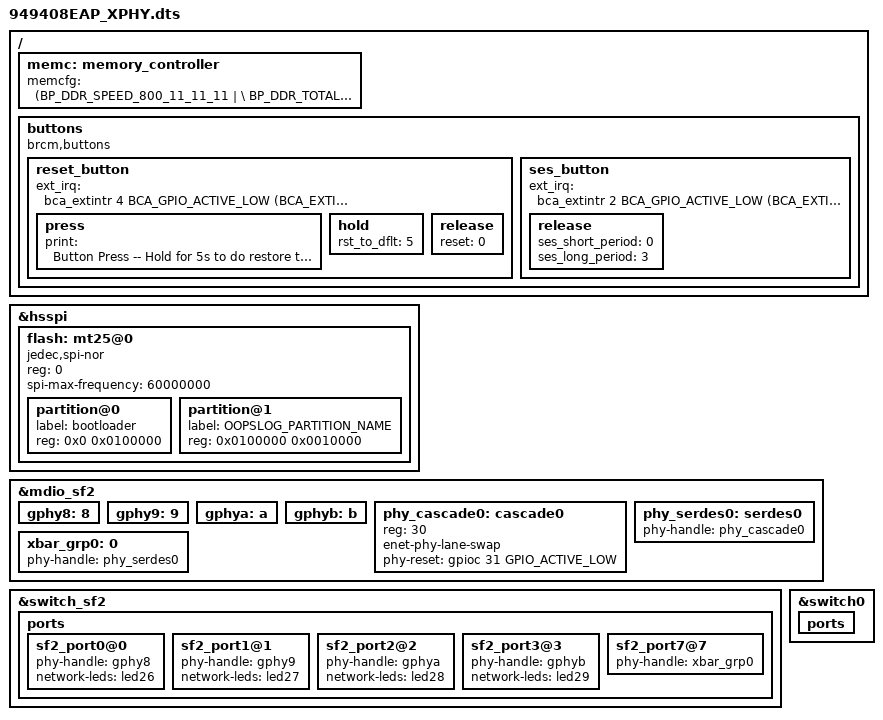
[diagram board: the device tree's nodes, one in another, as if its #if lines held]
#include "4908.dtsi"
#include "949408EAP_leds.dtsi"

/ {
    memc: memory_controller {
        memcfg = <(BP_DDR_SPEED_800_11_11_11 | \
                   BP_DDR_TOTAL_SIZE_1024MB  | \
                   BP_DDR_DEVICE_WIDTH_16    | \
                   BP_DDR_TOTAL_WIDTH_32BIT  | \
                   BP_DDR_SSC_CONFIG_1)>;
    };

	buttons {
		compatible = "brcm,buttons";
		reset_button {
			ext_irq = <&bca_extintr 4 BCA_GPIO_ACTIVE_LOW (BCA_EXTINTR_TYPE_LOW_LEVEL | BCA_EXTINTR_TYPE_SENSE_LEVEL)>;
			press {
				print = "Button Press -- Hold for 5s to do restore to default";
			};
			hold {
				rst_to_dflt = <5>;
			};
			release {
				reset = <0>;
			};	
		};
		ses_button {
			ext_irq = <&bca_extintr 2 BCA_GPIO_ACTIVE_LOW (BCA_EXTINTR_TYPE_LOW_LEVEL | BCA_EXTINTR_TYPE_SENSE_LEVEL)>;
			release {
				ses_short_period = <0>;
				ses_long_period = <3>;
			};
		};
	};
};

&hsspi { 
      flash: mt25@0 {
      status = "okay";
      compatible = "jedec,spi-nor";
      reg = <0>; /* chip select 0 */
      spi-max-frequency = <60000000>;
      #address-cells = <1>;
      #size-cells = <1>;

#if defined (CONFIG_BCM_HND_EAP)
      partition@0 {
           label = "bootloader";
           reg = <0x0 0x0100000>;
      };
#if defined (OOPSLOG_PARTITION_NAME)
      partition@1 {
           label = OOPSLOG_PARTITION_NAME;
           reg = <0x0100000 0x0010000>;
      };
#endif
#endif
      };
};

&mdio_sf2 {
	/* PHYs directly connected to SF2 */
	gphy8:8 {
		status = "okay";
	};
	gphy9:9 {
		status = "okay";
	};
	gphya:a {
		status = "okay";
	};
	gphyb:b {
		status = "okay";
	};

	/* Cascade PHY */
	phy_cascade0:cascade0 {
		reg = <30>;
		enet-phy-lane-swap;
		phy-reset = <&gpioc 31 GPIO_ACTIVE_LOW>;
		status = "okay";
	};
	
	/* PHYs connected to crossbar */
	phy_serdes0:serdes0 {
		phy-handle = <&phy_cascade0>;
		status = "okay";
	};

	/* Crossbar groups */
	xbar_grp0:0 {
		phy-handle = <&phy_serdes0>;
		status = "okay";
	};
};

&switch_sf2 {
	ports {
		sf2_port0@0 {
			phy-handle = <&gphy8>;
			network-leds = <&led26>;
			status = "okay";
		};

		sf2_port1@1 {
			phy-handle = <&gphy9>;
			network-leds = <&led27>;
			status = "okay";
		};

		sf2_port2@2 {
			phy-handle = <&gphya>;
			network-leds = <&led28>;
			status = "okay";
		};

		sf2_port3@3 {
			phy-handle = <&gphyb>;
			network-leds = <&led29>;
			status = "okay";
		};

		sf2_port7@7 {
			phy-handle = <&xbar_grp0>;
			status = "okay";
		};

	};
};

&switch0 {
	ports {
	};
};
